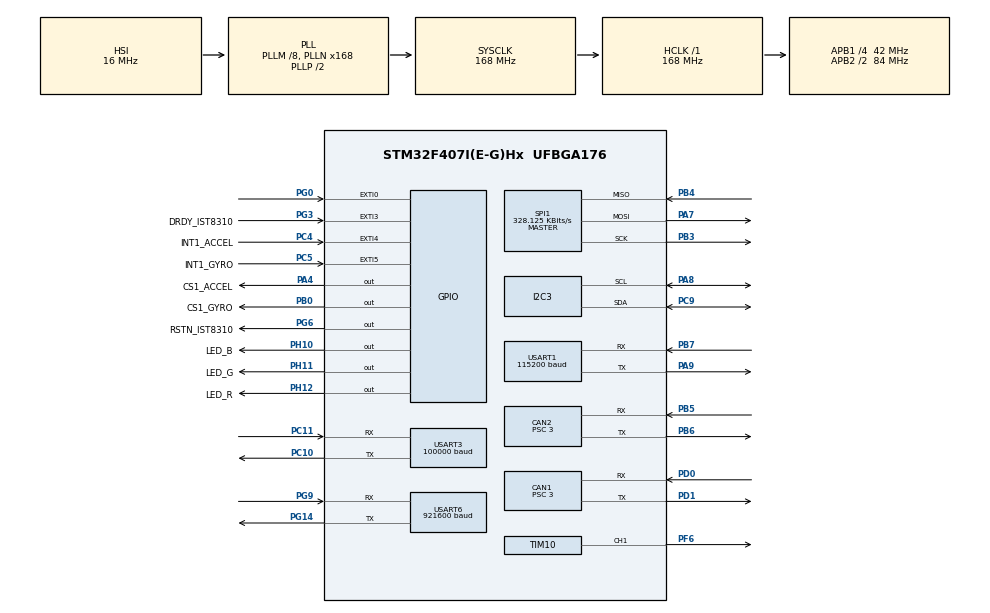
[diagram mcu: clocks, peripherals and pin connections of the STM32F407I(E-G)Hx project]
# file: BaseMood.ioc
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CAN1.BS1=CAN_BS1_11TQ
CAN1.BS2=CAN_BS2_2TQ
CAN1.CalculateBaudRate=1000000
CAN1.CalculateTimeBit=1000
CAN1.CalculateTimeQuantum=71.42857142857143
CAN1.Prescaler=3
CAN2.BS1=CAN_BS1_11TQ
CAN2.BS2=CAN_BS2_2TQ
CAN2.CalculateBaudRate=1000000
CAN2.CalculateTimeBit=1000
CAN2.CalculateTimeQuantum=71.42857142857143
CAN2.Prescaler=3
Dma.Request0=SPI1_RX
Dma.Request1=SPI1_TX
Dma.Request2=USART3_RX
Dma.Request3=USART6_RX
Dma.Request4=USART6_TX
Dma.Request5=USART1_RX
Dma.Request6=USART1_TX
Dma.SPI1_RX.0.Direction=DMA_PERIPH_TO_MEMORY
Dma.SPI1_RX.0.FIFOMode=DMA_FIFOMODE_DISABLE
Dma.SPI1_RX.0.Instance=DMA2_Stream2
Dma.SPI1_RX.0.MemDataAlignment=DMA_MDATAALIGN_BYTE
Dma.SPI1_RX.0.MemInc=DMA_MINC_ENABLE
Dma.SPI1_RX.0.Mode=DMA_NORMAL
Dma.SPI1_RX.0.PeriphDataAlignment=DMA_PDATAALIGN_BYTE
Dma.SPI1_RX.0.PeriphInc=DMA_PINC_DISABLE
Dma.SPI1_RX.0.Priority=DMA_PRIORITY_VERY_HIGH
Dma.SPI1_TX.1.Direction=DMA_MEMORY_TO_PERIPH
Dma.SPI1_TX.1.FIFOMode=DMA_FIFOMODE_DISABLE
Dma.SPI1_TX.1.Instance=DMA2_Stream3
Dma.SPI1_TX.1.MemDataAlignment=DMA_MDATAALIGN_BYTE
Dma.SPI1_TX.1.MemInc=DMA_MINC_ENABLE
Dma.SPI1_TX.1.Mode=DMA_NORMAL
Dma.SPI1_TX.1.PeriphDataAlignment=DMA_PDATAALIGN_BYTE
Dma.SPI1_TX.1.PeriphInc=DMA_PINC_DISABLE
Dma.SPI1_TX.1.Priority=DMA_PRIORITY_HIGH
Dma.USART1_RX.5.Direction=DMA_PERIPH_TO_MEMORY
Dma.USART1_RX.5.FIFOMode=DMA_FIFOMODE_DISABLE
Dma.USART1_RX.5.Instance=DMA2_Stream5
Dma.USART1_RX.5.MemDataAlignment=DMA_MDATAALIGN_BYTE
Dma.USART1_RX.5.MemInc=DMA_MINC_ENABLE
Dma.USART1_RX.5.Mode=DMA_CIRCULAR
Dma.USART1_RX.5.PeriphDataAlignment=DMA_PDATAALIGN_BYTE
Dma.USART1_RX.5.PeriphInc=DMA_PINC_DISABLE
Dma.USART1_RX.5.Priority=DMA_PRIORITY_MEDIUM
Dma.USART1_TX.6.Direction=DMA_MEMORY_TO_PERIPH
Dma.USART1_TX.6.FIFOMode=DMA_FIFOMODE_DISABLE
Dma.USART1_TX.6.Instance=DMA2_Stream7
Dma.USART1_TX.6.MemDataAlignment=DMA_MDATAALIGN_BYTE
Dma.USART1_TX.6.MemInc=DMA_MINC_ENABLE
Dma.USART1_TX.6.Mode=DMA_NORMAL
Dma.USART1_TX.6.PeriphDataAlignment=DMA_PDATAALIGN_BYTE
Dma.USART1_TX.6.PeriphInc=DMA_PINC_DISABLE
Dma.USART1_TX.6.Priority=DMA_PRIORITY_MEDIUM
Dma.USART3_RX.2.Direction=DMA_PERIPH_TO_MEMORY
Dma.USART3_RX.2.FIFOMode=DMA_FIFOMODE_DISABLE
Dma.USART3_RX.2.Instance=DMA1_Stream1
Dma.USART3_RX.2.MemDataAlignment=DMA_MDATAALIGN_BYTE
Dma.USART3_RX.2.MemInc=DMA_MINC_ENABLE
Dma.USART3_RX.2.Mode=DMA_CIRCULAR
Dma.USART3_RX.2.PeriphDataAlignment=DMA_PDATAALIGN_BYTE
Dma.USART3_RX.2.PeriphInc=DMA_PINC_DISABLE
Dma.USART3_RX.2.Priority=DMA_PRIORITY_MEDIUM
Dma.USART6_RX.3.Direction=DMA_PERIPH_TO_MEMORY
Dma.USART6_RX.3.FIFOMode=DMA_FIFOMODE_DISABLE
Dma.USART6_RX.3.Instance=DMA2_Stream1
Dma.USART6_RX.3.MemDataAlignment=DMA_MDATAALIGN_BYTE
Dma.USART6_RX.3.MemInc=DMA_MINC_ENABLE
Dma.USART6_RX.3.Mode=DMA_CIRCULAR
Dma.USART6_RX.3.PeriphDataAlignment=DMA_PDATAALIGN_BYTE
Dma.USART6_RX.3.PeriphInc=DMA_PINC_DISABLE
Dma.USART6_RX.3.Priority=DMA_PRIORITY_HIGH
Dma.USART6_TX.4.Direction=DMA_MEMORY_TO_PERIPH
Dma.USART6_TX.4.FIFOMode=DMA_FIFOMODE_DISABLE
Dma.USART6_TX.4.Instance=DMA2_Stream6
Dma.USART6_TX.4.MemDataAlignment=DMA_MDATAALIGN_BYTE
Dma.USART6_TX.4.MemInc=DMA_MINC_ENABLE
Dma.USART6_TX.4.Mode=DMA_NORMAL
Dma.USART6_TX.4.PeriphDataAlignment=DMA_PDATAALIGN_BYTE
Dma.USART6_TX.4.PeriphInc=DMA_PINC_DISABLE
Dma.USART6_TX.4.Priority=DMA_PRIORITY_HIGH
FREERTOS.INCLUDE_pcTaskGetTaskName=1
FREERTOS.INCLUDE_uxTaskGetStackHighWaterMark2=1
FREERTOS.INCLUDE_vTaskCleanUpResources=1
FREERTOS.INCLUDE_xEventGroupSetBitFromISR=1
FREERTOS.INCLUDE_xSemaphoreGetMutexHolder=1
FREERTOS.INCLUDE_xTaskAbortDelay=1
FREERTOS.INCLUDE_xTaskGetHandle=1
FREERTOS.Tasks01=defaultTask,24,128,StartDefaultTask,Default,NULL,Dynamic,NULL,NULL;imuTask,49,1024,INS_task,As weak,NULL,Dynamic,NULL,NULL;buzr,24,128,buzzer_effects_task,As weak,NULL,Dynamic,NULL,NULL;DualBoard,48,256,DualBoardTask,As weak,NULL,Static,Dual_Board_TranBuffer,Dual_Board_TranControlBlock;Chassis,47,128,ChassisTask,As weak,NULL,Static,ChassisBuffer,ChassisControlBlock;Gimbal,47,128,GimbalTask,As weak,NULL,Static,GimbalBuffer,GimbalControlBlock;Shooting,47,128,ShootingTask,As weak,NULL,Static,ShootingBuffer,ShootingControlBlock;CMDUpdate,48,128,CMDUpdateTask,As weak,NULL,Static,CMDUpdateBuffer,CMDUpdateControlBlock;SBUS,48,128,SBUSTask,As weak,NULL,Static,SBUSBuffer,SBUSControlBlock;RCUpdate,48,128,RCUpdateTask,As weak,NULL,Static,RCUpdateBuffer,RCUpdateControlBlock;DJIMotorCheck,24,128,DJIMotorCheckTask,As weak,NULL,Static,DJIMotorCheckBuffer,DJIMotorCheckControlBlock;ShootingPushRod,47,128,ShootingPushRodTask,As weak,NULL,Static,PushRodBuffer,PushRodControlBlock;ShootingLoad,47,128,ShootingLoadTask,As weak,NULL,Static,ShootingLoadBuffer,ShootingLoadControlBlock;AutoAim,48,128,AutoAimTask,As weak,NULL,Static,AutoBuffer,AutoControlBlock;Referee,40,128,RefereeTask,As weak,NULL,Static,RefereeBuffer,RefereeControlBlock;VT,48,128,VTTask,As weak,NULL,Static,VTBuffer,VTControlBlock;PlyerUI,47,128,PlyerUITask,As weak,NULL,Static,PlyerUIBuffer,PlyerUIControlBlock;Printf,24,1024,PrintfTask,As weak,NULL,Static,PrintfBuffer,PrintfControlBlock
FREERTOS.configENABLE_FPU=1
I2C3.I2C_Mode=I2C_Fast
Mcu.Family=STM32F4
Mcu.Name=STM32F407I(E-G)Hx
Mcu.Package=UFBGA176
NVIC.CAN1_RX0_IRQn=true\:6\:0\:true\:false\:true\:true\:true\:true\:true
NVIC.CAN1_RX1_IRQn=true\:6\:0\:true\:false\:true\:true\:true\:true\:true
NVIC.CAN2_RX0_IRQn=true\:6\:0\:true\:false\:true\:true\:true\:true\:true
NVIC.CAN2_RX1_IRQn=true\:6\:0\:true\:false\:true\:true\:true\:true\:true
NVIC.DMA1_Stream1_IRQn=true\:15\:0\:true\:false\:true\:true\:false\:true\:true
NVIC.DMA2_Stream1_IRQn=true\:5\:0\:false\:false\:true\:true\:false\:true\:true
NVIC.DMA2_Stream2_IRQn=true\:5\:0\:true\:false\:false\:false\:false\:true\:true
NVIC.DMA2_Stream3_IRQn=true\:5\:0\:false\:false\:false\:true\:false\:true\:true
NVIC.DMA2_Stream5_IRQn=true\:5\:0\:false\:false\:true\:true\:false\:true\:true
NVIC.DMA2_Stream6_IRQn=true\:5\:0\:false\:false\:true\:true\:false\:true\:true
NVIC.DMA2_Stream7_IRQn=true\:5\:0\:false\:false\:true\:true\:false\:true\:true
NVIC.EXTI0_IRQn=true\:5\:0\:false\:false\:true\:true\:true\:true\:true
NVIC.EXTI3_IRQn=true\:5\:0\:false\:false\:true\:true\:true\:true\:true
NVIC.EXTI4_IRQn=true\:5\:0\:false\:false\:true\:true\:true\:true\:true
NVIC.EXTI9_5_IRQn=true\:5\:0\:false\:false\:true\:true\:true\:true\:true
NVIC.PriorityGroup=NVIC_PRIORITYGROUP_4
NVIC.TIM2_IRQn=true\:15\:0\:false\:false\:true\:false\:true\:true\:true
NVIC.TimeBase=TIM2_IRQn
NVIC.TimeBaseIP=TIM2
NVIC.USART1_IRQn=true\:5\:0\:false\:false\:true\:true\:true\:true\:true
NVIC.USART3_IRQn=true\:15\:0\:true\:false\:true\:true\:true\:true\:true
NVIC.USART6_IRQn=true\:5\:0\:false\:false\:true\:true\:true\:true\:true
PA13.Mode=Serial_Wire
PA13.Signal=SYS_JTMS-SWDIO
PA14.Mode=Serial_Wire
PA14.Signal=SYS_JTCK-SWCLK
PA4.GPIO_Label=CS1_ACCEL
PA4.GPIO_PuPd=GPIO_PULLUP
PA4.GPIO_Speed=GPIO_SPEED_FREQ_HIGH
PA4.PinState=GPIO_PIN_SET
PA4.Signal=GPIO_Output
PA7.Mode=Full_Duplex_Master
PA7.Signal=SPI1_MOSI
PA8.GPIO_Pu=GPIO_PULLUP
PA8.Mode=I2C
PA8.Signal=I2C3_SCL
PA9.Mode=Asynchronous
PA9.Signal=USART1_TX
PB0.GPIO_Label=CS1_GYRO
PB0.GPIO_PuPd=GPIO_PULLUP
PB0.GPIO_Speed=GPIO_SPEED_FREQ_HIGH
PB0.PinState=GPIO_PIN_SET
PB0.Signal=GPIO_Output
PB3.Mode=Full_Duplex_Master
PB3.Signal=SPI1_SCK
PB4.Mode=Full_Duplex_Master
PB4.Signal=SPI1_MISO
PB5.Mode=CAN_Activate
PB5.Signal=CAN2_RX
PB6.Mode=CAN_Activate
PB6.Signal=CAN2_TX
PB7.Mode=Asynchronous
PB7.Signal=USART1_RX
PC10.Mode=Asynchronous
PC10.Signal=USART3_TX
PC11.Mode=Asynchronous
PC11.Signal=USART3_RX
PC4.GPIO_Label=INT1_ACCEL
PC4.GPIO_ModeDefaultEXTI=GPIO_MODE_IT_FALLING
PC4.GPIO_PuPd=GPIO_PULLUP
PC4.Signal=GPXTI4
PC5.GPIO_Label=INT1_GYRO
PC5.GPIO_ModeDefaultEXTI=GPIO_MODE_IT_FALLING
PC5.GPIO_PuPd=GPIO_PULLUP
PC5.Signal=GPXTI5
PC9.GPIO_Pu=GPIO_PULLUP
PC9.Mode=I2C
PC9.Signal=I2C3_SDA
PD0.Mode=CAN_Activate
PD0.Signal=CAN1_RX
PD1.Mode=CAN_Activate
PD1.Signal=CAN1_TX
PF6.Signal=S_TIM10_CH1
PG0.GPIO_ModeDefaultEXTI=GPIO_MODE_IT_FALLING
PG0.GPIO_PuPd=GPIO_PULLUP
PG0.Signal=GPXTI0
PG14.Mode=Asynchronous
PG14.Signal=USART6_TX
PG3.GPIO_Label=DRDY_IST8310
PG3.GPIO_PuPd=GPIO_PULLUP
PG3.Signal=GPXTI3
PG6.GPIO_Label=RSTN_IST8310
PG6.GPIO_PuPd=GPIO_PULLUP
PG6.GPIO_Speed=GPIO_SPEED_FREQ_MEDIUM
PG6.PinState=GPIO_PIN_SET
PG6.Signal=GPIO_Output
PG9.Mode=Asynchronous
PG9.Signal=USART6_RX
PH10.GPIO_Label=LED_B
PH10.GPIO_PuPd=GPIO_PULLUP
PH10.Signal=GPIO_Output
PH11.GPIO_Label=LED_G
PH11.Signal=GPIO_Output
PH12.GPIO_Label=LED_R
PH12.Signal=GPIO_Output
ProjectManager.HeapSize=0x200
ProjectManager.StackSize=0x400
ProjectManager.TargetToolchain=MDK-ARM V5.32
RCC.48MHZClocksFreq_Value=84000000
RCC.AHBFreq_Value=168000000
RCC.APB1CLKDivider=RCC_HCLK_DIV4
RCC.APB1Freq_Value=42000000
RCC.APB1TimFreq_Value=84000000
RCC.APB2CLKDivider=RCC_HCLK_DIV2
RCC.APB2Freq_Value=84000000
RCC.APB2TimFreq_Value=168000000
RCC.CortexFreq_Value=168000000
RCC.HCLKFreq_Value=168000000
RCC.HSE_VALUE=25000000
RCC.HSI_VALUE=16000000
RCC.LSE_VALUE=32768
RCC.PLLM=8
RCC.PLLN=168
RCC.SYSCLKFreq_VALUE=168000000
RCC.SYSCLKSource=RCC_SYSCLKSOURCE_PLLCLK
RCC.VCOOutputFreq_Value=336000000
SH.S_TIM10_CH1.0=TIM10_CH1,PWM Generation1 CH1
SPI1.BaudRatePrescaler=SPI_BAUDRATEPRESCALER_256
SPI1.CLKPhase=SPI_PHASE_2EDGE
SPI1.CLKPolarity=SPI_POLARITY_HIGH
SPI1.CalculateBaudRate=328.125 KBits/s
SPI1.Direction=SPI_DIRECTION_2LINES
SPI1.Mode=SPI_MODE_MASTER
SPI1.VirtualType=VM_MASTER
TIM10.Channel=TIM_CHANNEL_1
TIM10.Period=4999
USART1.BaudRate=115200
USART1.VirtualMode=VM_ASYNC
USART3.BaudRate=100000
USART3.Parity=PARITY_EVEN
USART3.StopBits=STOPBITS_2
USART3.VirtualMode=VM_ASYNC
USART3.WordLength=WORDLENGTH_9B
USART6.BaudRate=921600
USART6.VirtualMode=VM_ASYNC
VP_FREERTOS_VS_CMSIS_V2.Mode=CMSIS_V2
VP_SYS_VS_tim2.Mode=TIM2
VP_TIM10_VS_ClockSourceINT.Mode=Enable_Timer
board=custom

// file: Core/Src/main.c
/* USER CODE BEGIN Header */
/**
  ******************************************************************************
  * @file           : main.c
  * @brief          : Main program body
  ******************************************************************************
  * @attention
  *
  * Copyright (c) 2026 STMicroelectronics.
  * All rights reserved.
  *
  * This software is licensed under terms that can be found in the LICENSE file
  * in the root directory of this software component.
  * If no LICENSE file comes with this software, it is provided AS-IS.
  *
  ******************************************************************************
  */
/* USER CODE END Header */
#include "main.h"
#include "cmsis_os.h"
#include "can.h"
#include "dma.h"
#include "i2c.h"
#include "spi.h"
#include "tim.h"
#include "usart.h"
#include "gpio.h"

/* USER CODE BEGIN Includes */
#include "bsp_delay.h"
#include "A_MCommon.h"

/* USER CODE END Includes */

void SystemClock_Config(void);
void MX_FREERTOS_Init(void);

int main(void)
{

  /* MCU Configuration--------------------------------------------------------*/

  /* Reset of all peripherals, Initializes the Flash interface and the Systick. */
  HAL_Init();

  /* Configure the system clock */
  SystemClock_Config();

  /* Initialize all configured peripherals */
  MX_GPIO_Init();
  MX_DMA_Init();
  MX_CAN1_Init();
  MX_CAN2_Init();
  MX_SPI1_Init();
  MX_I2C3_Init();
  MX_TIM10_Init();
  MX_USART3_UART_Init();
  MX_USART6_UART_Init();
  MX_USART1_UART_Init();
  /* USER CODE BEGIN 2 */
	delay_init();
	BSP_Init();

	//X_V2_Vel_Control(1,9,100,200,false);
	//X_V2_Origin_Modify_Params(1,true,2,0,1000,3000,200,500,200,true);
	//HAL_Delay(2000);
	//X_V2_En_Control(1,true,false);
	//X_V2_Origin_Trigger_Return(1,2,false);

  //HAL_Delay(3000);
  //X_V2_En_Control(1,false,false);

	// while(1)
	// {
	// 	//HAL_Delay(1);
	// 	//X_V2_Vel_Control(1,9,100,200,false);
	// }

	// ����USART1 DMAѭ�����գ���������+�������ж�

  /* USER CODE END 2 */

  /* Init scheduler */
  osKernelInitialize();

  /* Call init function for freertos objects (in cmsis_os2.c) */
  MX_FREERTOS_Init();

  /* Start scheduler */
  osKernelStart();

  /* We should never get here as control is now taken by the scheduler */

  /* Infinite loop */
  while (1)
  {

  }
}

void SystemClock_Config(void)
{
  RCC_OscInitTypeDef RCC_OscInitStruct = {0};
  RCC_ClkInitTypeDef RCC_ClkInitStruct = {0};

  /** Configure the main internal regulator output voltage
  */
  __HAL_RCC_PWR_CLK_ENABLE();
  __HAL_PWR_VOLTAGESCALING_CONFIG(PWR_REGULATOR_VOLTAGE_SCALE1);

  /** Initializes the RCC Oscillators according to the specified parameters
  * in the RCC_OscInitTypeDef structure.
  */
  RCC_OscInitStruct.OscillatorType = RCC_OSCILLATORTYPE_HSI;
  RCC_OscInitStruct.HSIState = RCC_HSI_ON;
  RCC_OscInitStruct.HSICalibrationValue = RCC_HSICALIBRATION_DEFAULT;
  RCC_OscInitStruct.PLL.PLLState = RCC_PLL_ON;
  RCC_OscInitStruct.PLL.PLLSource = RCC_PLLSOURCE_HSI;
  RCC_OscInitStruct.PLL.PLLM = 8;
  RCC_OscInitStruct.PLL.PLLN = 168;
  RCC_OscInitStruct.PLL.PLLP = RCC_PLLP_DIV2;
  RCC_OscInitStruct.PLL.PLLQ = 4;
  if (HAL_RCC_OscConfig(&RCC_OscInitStruct) != HAL_OK)
  {
    Error_Handler();
  }

  /** Initializes the CPU, AHB and APB buses clocks
  */
  RCC_ClkInitStruct.ClockType = RCC_CLOCKTYPE_HCLK|RCC_CLOCKTYPE_SYSCLK
                              |RCC_CLOCKTYPE_PCLK1|RCC_CLOCKTYPE_PCLK2;
  RCC_ClkInitStruct.SYSCLKSource = RCC_SYSCLKSOURCE_PLLCLK;
  RCC_ClkInitStruct.AHBCLKDivider = RCC_SYSCLK_DIV1;
  RCC_ClkInitStruct.APB1CLKDivider = RCC_HCLK_DIV4;
  RCC_ClkInitStruct.APB2CLKDivider = RCC_HCLK_DIV2;

  if (HAL_RCC_ClockConfig(&RCC_ClkInitStruct, FLASH_LATENCY_5) != HAL_OK)
  {
    Error_Handler();
  }
}

void HAL_TIM_PeriodElapsedCallback(TIM_HandleTypeDef *htim)
{
  if (htim->Instance == TIM2)
  {
    HAL_IncTick();
  }
}

void Error_Handler(void)
{
  __disable_irq();
  while (1)
  {
  }
}

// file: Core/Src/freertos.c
/* USER CODE BEGIN Header */
/**
  ******************************************************************************
  * File Name          : freertos.c
  * Description        : Code for freertos applications
  ******************************************************************************
  * @attention
  *
  * Copyright (c) 2026 STMicroelectronics.
  * All rights reserved.
  *
  * This software is licensed under terms that can be found in the LICENSE file
  * in the root directory of this software component.
  * If no LICENSE file comes with this software, it is provided AS-IS.
  *
  ******************************************************************************
  */
/* USER CODE END Header */

#include "FreeRTOS.h"
#include "task.h"
#include "main.h"
#include "cmsis_os.h"

/* USER CODE BEGIN Includes */

#include "INS_task.h"
#include "sound_effects_task.h"
#include "bsp_SBUS.h"

/* USER CODE END Includes */

typedef StaticTask_t osStaticThreadDef_t;

/* Definitions for defaultTask */
osThreadId_t defaultTaskHandle;
const osThreadAttr_t defaultTask_attributes = {
  .name = "defaultTask",
  .stack_size = 128 * 4,
  .priority = (osPriority_t) osPriorityNormal,
};
/* Definitions for imuTask */
osThreadId_t imuTaskHandle;
const osThreadAttr_t imuTask_attributes = {
  .name = "imuTask",
  .stack_size = 1024 * 4,
  .priority = (osPriority_t) osPriorityRealtime1,
};
/* Definitions for buzr */
osThreadId_t buzrHandle;
const osThreadAttr_t buzr_attributes = {
  .name = "buzr",
  .stack_size = 128 * 4,
  .priority = (osPriority_t) osPriorityNormal,
};
/* Definitions for DualBoard */
osThreadId_t DualBoardHandle;
uint32_t Dual_Board_TranBuffer[ 256 ];
osStaticThreadDef_t Dual_Board_TranControlBlock;
const osThreadAttr_t DualBoard_attributes = {
  .name = "DualBoard",
  .cb_mem = &Dual_Board_TranControlBlock,
  .cb_size = sizeof(Dual_Board_TranControlBlock),
  .stack_mem = &Dual_Board_TranBuffer[0],
  .stack_size = sizeof(Dual_Board_TranBuffer),
  .priority = (osPriority_t) osPriorityRealtime,
};
/* Definitions for Chassis */
osThreadId_t ChassisHandle;
uint32_t ChassisBuffer[ 128 ];
osStaticThreadDef_t ChassisControlBlock;
const osThreadAttr_t Chassis_attributes = {
  .name = "Chassis",
  .cb_mem = &ChassisControlBlock,
  .cb_size = sizeof(ChassisControlBlock),
  .stack_mem = &ChassisBuffer[0],
  .stack_size = sizeof(ChassisBuffer),
  .priority = (osPriority_t) osPriorityHigh7,
};
/* Definitions for Gimbal */
osThreadId_t GimbalHandle;
uint32_t GimbalBuffer[ 128 ];
osStaticThreadDef_t GimbalControlBlock;
const osThreadAttr_t Gimbal_attributes = {
  .name = "Gimbal",
  .cb_mem = &GimbalControlBlock,
  .cb_size = sizeof(GimbalControlBlock),
  .stack_mem = &GimbalBuffer[0],
  .stack_size = sizeof(GimbalBuffer),
  .priority = (osPriority_t) osPriorityHigh7,
};
/* Definitions for Shooting */
osThreadId_t ShootingHandle;
uint32_t ShootingBuffer[ 128 ];
osStaticThreadDef_t ShootingControlBlock;
const osThreadAttr_t Shooting_attributes = {
  .name = "Shooting",
  .cb_mem = &ShootingControlBlock,
  .cb_size = sizeof(ShootingControlBlock),
  .stack_mem = &ShootingBuffer[0],
  .stack_size = sizeof(ShootingBuffer),
  .priority = (osPriority_t) osPriorityHigh7,
};
/* Definitions for CMDUpdate */
osThreadId_t CMDUpdateHandle;
uint32_t CMDUpdateBuffer[ 128 ];
osStaticThreadDef_t CMDUpdateControlBlock;
const osThreadAttr_t CMDUpdate_attributes = {
  .name = "CMDUpdate",
  .cb_mem = &CMDUpdateControlBlock,
  .cb_size = sizeof(CMDUpdateControlBlock),
  .stack_mem = &CMDUpdateBuffer[0],
  .stack_size = sizeof(CMDUpdateBuffer),
  .priority = (osPriority_t) osPriorityRealtime,
};
/* Definitions for SBUS */
osThreadId_t SBUSHandle;
uint32_t SBUSBuffer[ 128 ];
osStaticThreadDef_t SBUSControlBlock;
const osThreadAttr_t SBUS_attributes = {
  .name = "SBUS",
  .cb_mem = &SBUSControlBlock,
  .cb_size = sizeof(SBUSControlBlock),
  .stack_mem = &SBUSBuffer[0],
  .stack_size = sizeof(SBUSBuffer),
  .priority = (osPriority_t) osPriorityRealtime,
};
/* Definitions for RCUpdate */
osThreadId_t RCUpdateHandle;
uint32_t RCUpdateBuffer[ 128 ];
osStaticThreadDef_t RCUpdateControlBlock;
const osThreadAttr_t RCUpdate_attributes = {
  .name = "RCUpdate",
  .cb_mem = &RCUpdateControlBlock,
  .cb_size = sizeof(RCUpdateControlBlock),
  .stack_mem = &RCUpdateBuffer[0],
  .stack_size = sizeof(RCUpdateBuffer),
  .priority = (osPriority_t) osPriorityRealtime,
};
/* Definitions for DJIMotorCheck */
osThreadId_t DJIMotorCheckHandle;
uint32_t DJIMotorCheckBuffer[ 128 ];
osStaticThreadDef_t DJIMotorCheckControlBlock;
const osThreadAttr_t DJIMotorCheck_attributes = {
  .name = "DJIMotorCheck",
  .cb_mem = &DJIMotorCheckControlBlock,
  .cb_size = sizeof(DJIMotorCheckControlBlock),
  .stack_mem = &DJIMotorCheckBuffer[0],
  .stack_size = sizeof(DJIMotorCheckBuffer),
  .priority = (osPriority_t) osPriorityNormal,
};
/* Definitions for ShootingPushRod */
osThreadId_t ShootingPushRodHandle;
uint32_t PushRodBuffer[ 128 ];
osStaticThreadDef_t PushRodControlBlock;
const osThreadAttr_t ShootingPushRod_attributes = {
  .name = "ShootingPushRod",
  .cb_mem = &PushRodControlBlock,
  .cb_size = sizeof(PushRodControlBlock),
  .stack_mem = &PushRodBuffer[0],
  .stack_size = sizeof(PushRodBuffer),
  .priority = (osPriority_t) osPriorityHigh7,
};
/* Definitions for ShootingLoad */
osThreadId_t ShootingLoadHandle;
uint32_t ShootingLoadBuffer[ 128 ];
osStaticThreadDef_t ShootingLoadControlBlock;
const osThreadAttr_t ShootingLoad_attributes = {
  .name = "ShootingLoad",
  .cb_mem = &ShootingLoadControlBlock,
  .cb_size = sizeof(ShootingLoadControlBlock),
  .stack_mem = &ShootingLoadBuffer[0],
  .stack_size = sizeof(ShootingLoadBuffer),
  .priority = (osPriority_t) osPriorityHigh7,
};
/* Definitions for AutoAim */
osThreadId_t AutoAimHandle;
uint32_t AutoBuffer[ 128 ];
osStaticThreadDef_t AutoControlBlock;
const osThreadAttr_t AutoAim_attributes = {
  .name = "AutoAim",
  .cb_mem = &AutoControlBlock,
  .cb_size = sizeof(AutoControlBlock),
  .stack_mem = &AutoBuffer[0],
  .stack_size = sizeof(AutoBuffer),
  .priority = (osPriority_t) osPriorityRealtime,
};
/* Definitions for Referee */
osThreadId_t RefereeHandle;
uint32_t RefereeBuffer[ 128 ];
osStaticThreadDef_t RefereeControlBlock;
const osThreadAttr_t Referee_attributes = {
  .name = "Referee",
  .cb_mem = &RefereeControlBlock,
  .cb_size = sizeof(RefereeControlBlock),
  .stack_mem = &RefereeBuffer[0],
  .stack_size = sizeof(RefereeBuffer),
  .priority = (osPriority_t) osPriorityHigh,
};
/* Definitions for VT */
osThreadId_t VTHandle;
uint32_t VTBuffer[ 128 ];
osStaticThreadDef_t VTControlBlock;
const osThreadAttr_t VT_attributes = {
  .name = "VT",
  .cb_mem = &VTControlBlock,
  .cb_size = sizeof(VTControlBlock),
  .stack_mem = &VTBuffer[0],
  .stack_size = sizeof(VTBuffer),
  .priority = (osPriority_t) osPriorityRealtime,
};
/* Definitions for PlyerUI */
osThreadId_t PlyerUIHandle;
uint32_t PlyerUIBuffer[ 128 ];
osStaticThreadDef_t PlyerUIControlBlock;
const osThreadAttr_t PlyerUI_attributes = {
  .name = "PlyerUI",
  .cb_mem = &PlyerUIControlBlock,
  .cb_size = sizeof(PlyerUIControlBlock),
  .stack_mem = &PlyerUIBuffer[0],
  .stack_size = sizeof(PlyerUIBuffer),
  .priority = (osPriority_t) osPriorityHigh7,
};
/* Definitions for Printf */
osThreadId_t PrintfHandle;
uint32_t PrintfBuffer[ 1024 ];
osStaticThreadDef_t PrintfControlBlock;
const osThreadAttr_t Printf_attributes = {
  .name = "Printf",
  .cb_mem = &PrintfControlBlock,
  .cb_size = sizeof(PrintfControlBlock),
  .stack_mem = &PrintfBuffer[0],
  .stack_size = sizeof(PrintfBuffer),
  .priority = (osPriority_t) osPriorityNormal,
};

void StartDefaultTask(void *argument);
void DualBoardTask(void *argument);
void ChassisTask(void *argument);
void GimbalTask(void *argument);
void ShootingTask(void *argument);
void CMDUpdateTask(void *argument);
void SBUSTask(void *argument);
void RCUpdateTask(void *argument);
void DJIMotorCheckTask(void *argument);
void ShootingPushRodTask(void *argument);
void ShootingLoadTask(void *argument);
void AutoAimTask(void *argument);
void RefereeTask(void *argument);
void VTTask(void *argument);
void PlyerUITask(void *argument);
void PrintfTask(void *argument);

void MX_FREERTOS_Init(void); /* (MISRA C 2004 rule 8.1) */

void MX_FREERTOS_Init(void) {

  /* Create the thread(s) */
  /* creation of defaultTask */
  defaultTaskHandle = osThreadNew(StartDefaultTask, NULL, &defaultTask_attributes);

  /* creation of imuTask */
  imuTaskHandle = osThreadNew(INS_task, NULL, &imuTask_attributes);

  /* creation of buzr */
  buzrHandle = osThreadNew(buzzer_effects_task, NULL, &buzr_attributes);

  /* creation of DualBoard */
  DualBoardHandle = osThreadNew(DualBoardTask, NULL, &DualBoard_attributes);

  /* creation of Chassis */
  ChassisHandle = osThreadNew(ChassisTask, NULL, &Chassis_attributes);

  /* creation of Gimbal */
  GimbalHandle = osThreadNew(GimbalTask, NULL, &Gimbal_attributes);

  /* creation of Shooting */
  ShootingHandle = osThreadNew(ShootingTask, NULL, &Shooting_attributes);

  /* creation of CMDUpdate */
  CMDUpdateHandle = osThreadNew(CMDUpdateTask, NULL, &CMDUpdate_attributes);

  /* creation of SBUS */
  SBUSHandle = osThreadNew(SBUSTask, NULL, &SBUS_attributes);

  /* creation of RCUpdate */
  RCUpdateHandle = osThreadNew(RCUpdateTask, NULL, &RCUpdate_attributes);

  /* creation of DJIMotorCheck */
  DJIMotorCheckHandle = osThreadNew(DJIMotorCheckTask, NULL, &DJIMotorCheck_attributes);

  /* creation of ShootingPushRod */
  ShootingPushRodHandle = osThreadNew(ShootingPushRodTask, NULL, &ShootingPushRod_attributes);

  /* creation of ShootingLoad */
  ShootingLoadHandle = osThreadNew(ShootingLoadTask, NULL, &ShootingLoad_attributes);

  /* creation of AutoAim */
  AutoAimHandle = osThreadNew(AutoAimTask, NULL, &AutoAim_attributes);

  /* creation of Referee */
  RefereeHandle = osThreadNew(RefereeTask, NULL, &Referee_attributes);

  /* creation of VT */
  VTHandle = osThreadNew(VTTask, NULL, &VT_attributes);

  /* creation of PlyerUI */
  PlyerUIHandle = osThreadNew(PlyerUITask, NULL, &PlyerUI_attributes);

  /* creation of Printf */
  PrintfHandle = osThreadNew(PrintfTask, NULL, &Printf_attributes);

  /* USER CODE BEGIN RTOS_THREADS */
  /* add threads, ... */

	//UAP_FreeRTOS_Init();

  /* USER CODE END RTOS_THREADS */

}

void StartDefaultTask(void *argument)
{
  /* USER CODE BEGIN StartDefaultTask */
  /* Infinite loop */

//	static uint16_t timecounttest = 0;
//	buzzer_t *buzzer = get_buzzer_effect_point();
//	buzzer->work = FALSE;
//	buzzer->work = TRUE;

  for(;;)
  {
    osDelay(10);
  }
  /* USER CODE END StartDefaultTask */
}

__weak void DualBoardTask(void *argument)
{
  for(;;)
  {
		osDelay(1);
  }
}

__weak void ChassisTask(void *argument)
{
  for(;;)
  {
    osDelay(1);
  }
}

__weak void GimbalTask(void *argument)
{
  for(;;)
  {
    osDelay(1);
  }
}

__weak void ShootingTask(void *argument)
{
  for(;;)
  {
    osDelay(1);
  }
}

__weak void CMDUpdateTask(void *argument)
{
  for(;;)
  {
    osDelay(1);
  }
}

__weak void SBUSTask(void *argument)
{
  for(;;)
  {
    osDelay(1);
  }
}

__weak void RCUpdateTask(void *argument)
{
  for(;;)
  {
    osDelay(1);
  }
}

__weak void DJIMotorCheckTask(void *argument)
{
  for(;;)
  {
    osDelay(1);
  }
}

__weak void ShootingPushRodTask(void *argument)
{
  for(;;)
  {
    osDelay(1);
  }
}

__weak void ShootingLoadTask(void *argument)
{
  for(;;)
  {
    osDelay(1);
  }
}

__weak void AutoAimTask(void *argument)
{
  for(;;)
  {
    osDelay(1);
  }
}

__weak void RefereeTask(void *argument)
{
  for(;;)
  {
    osDelay(1);
  }
}

__weak void VTTask(void *argument)
{
  for(;;)
  {
    osDelay(1);
  }
}

__weak void PlyerUITask(void *argument)
{
  for(;;)
  {
    osDelay(1);
  }
}

__weak void PrintfTask(void *argument)
{
  for(;;)
  {
    osDelay(1);
  }
}
